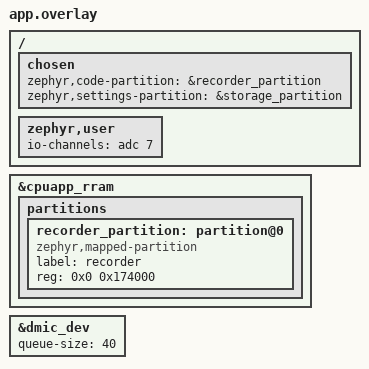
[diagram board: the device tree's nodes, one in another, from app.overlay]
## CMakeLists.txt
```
cmake_minimum_required(VERSION 3.20.0)
find_package(Zephyr REQUIRED HINTS $ENV{ZEPHYR_BASE})
project(recorder)

include(${CMAKE_CURRENT_SOURCE_DIR}/../lib/opus.cmake)

target_sources(app PRIVATE src/main.c src/audio.c src/ble.c src/battery.c src/agc.c)
target_link_libraries(app PRIVATE opus)
```

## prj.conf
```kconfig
# ---- 基础 ----
CONFIG_PRINTK=y
CONFIG_GPIO=y
CONFIG_LOG=y
CONFIG_MAIN_STACK_SIZE=4096

# ---- 麦克风 ----
CONFIG_AUDIO=y
CONFIG_AUDIO_DMIC=y

# ---- 蓝牙 ----
CONFIG_BT=y
CONFIG_BT_PERIPHERAL=y
CONFIG_BT_DEVICE_NAME="Hark DT-1"
CONFIG_BT_MAX_CONN=1
# 无显示屏：LE Secure Connections Just Works，禁用 legacy pairing。
CONFIG_BT_SMP=y
CONFIG_BT_SMP_SC_PAIR_ONLY=y
CONFIG_BT_SMP_APP_PAIRING_ACCEPT=y
CONFIG_BT_BONDABLE=y
CONFIG_BT_MAX_PAIRED=2
CONFIG_BT_KEYS_OVERWRITE_OLDEST=n
# 同一手机忘记密钥后也能在按键窗口内重新配对；窗口外由 pairing_accept 拒绝。
CONFIG_BT_SMP_ALLOW_UNAUTH_OVERWRITE=y
CONFIG_BT_SETTINGS=y
CONFIG_SETTINGS=y
CONFIG_FLASH=y
CONFIG_FLASH_MAP=y
CONFIG_FLASH_PAGE_LAYOUT=y
CONFIG_ZMS=y
CONFIG_SETTINGS_ZMS=y
CONFIG_USE_DT_CODE_PARTITION=y
# 大包：一次通知能带一整帧 Opus
CONFIG_BT_L2CAP_TX_MTU=247
CONFIG_BT_BUF_ACL_TX_SIZE=251
CONFIG_BT_BUF_ACL_RX_SIZE=251
CONFIG_BT_CTLR_DATA_LENGTH_MAX=251
CONFIG_BT_BUF_ACL_TX_COUNT=10
CONFIG_BT_CONN_TX_MAX=10
CONFIG_BT_GAP_AUTO_UPDATE_CONN_PARAMS=y
CONFIG_BT_PERIPHERAL_PREF_MIN_INT=12
CONFIG_BT_PERIPHERAL_PREF_MAX_INT=24
CONFIG_BT_PERIPHERAL_PREF_LATENCY=0
CONFIG_BT_PERIPHERAL_PREF_TIMEOUT=400
CONFIG_BT_USER_DATA_LEN_UPDATE=y
CONFIG_BT_USER_PHY_UPDATE=y

# ---- Opus 需要较大的栈和堆 ----
CONFIG_HEAP_MEM_POOL_SIZE=32768
CONFIG_FPU=y
CONFIG_BT_BUF_EVT_RX_COUNT=12

# ---- 电池电压 ----
CONFIG_ADC=y
CONFIG_REGULATOR=y

# ---- 出错自动重启：否则一旦出错芯片就停在原地，只有断电才能恢复 ----
CONFIG_REBOOT=y
CONFIG_RESET_ON_FATAL_ERROR=y
```

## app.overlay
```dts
/* 电池电压：ADC 通道 7 (P1.14)，经过 1/2 分压；vbat_pwr 负载开关控制分压电路的通断 */
/ {
	chosen {
		zephyr,code-partition = &recorder_partition;
		zephyr,settings-partition = &storage_partition;
	};
	zephyr,user {
		io-channels = <&adc 7>;
	};
};

/* 裸机程序仍从 0 启动。沿用 SDK 的 0x174000..0x17cfff settings 区，
 * 链接器限制程序不能进入该区，HEX 也不会包含该区。没有 MCUboot/双槽升级。 */
/delete-node/ &boot_partition;
/delete-node/ &slot0_partition;
/delete-node/ &slot1_partition;

&cpuapp_rram {
	partitions {
		recorder_partition: partition@0 {
			compatible = "zephyr,mapped-partition";
			label = "recorder";
			reg = <0x0 0x174000>;
		};
	};
};

/* PDM 驱动的接收队列默认只有 4 块 (80ms)。开口时要一口气编码 0.4 秒缓存（约 100ms），
 * 队列一满驱动就停麦且不恢复（2026-11-11 实测每几分钟一次）。40 块 = 0.8 秒，
 * 驱动另占 2 块，所以 audio.c 的 BLOCK_COUNT 必须 ≥ 42。 */
&dmic_dev {
	queue-size = <40>;
};
```

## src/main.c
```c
/* 全天语音记录器 —— 录音 + Opus 编码 + BLE 实时发送 */
#include <zephyr/kernel.h>
#include "app.h"

int main(void)
{
	printk("\n=== Hark DT-1 recorder start ===\n");
	if (ble_init() != 0) {
		printk("ERROR: BLE init failed\n");
		return 0;
	}
	audio_start();
	return 0;
}
```

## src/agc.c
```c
/*
 * 音频前处理：80Hz 高通滤波 + 固定线性增益（+12dB）+ 峰值限制防削波。
 *
 * - 高通：二阶巴特沃斯，去掉直流、走路震动、衣服摩擦、空调等低频轰鸣（人声基本在 100Hz 以上）。
 * - 固定增益：不再做 0~20dB 动态响度拉平，完整保留物理声压差（供手机端远近场判别，同时避免时变增益劣化声纹）。
 * - 峰值限制：放大后若瞬时峰值超过 -1dBFS（如咳嗽、碰壳），当帧立即压到刚好不削波，之后按 50dB/s 平滑恢复到 +12dB，无咔哒声。
 */
#include <math.h>
#include <zephyr/sys/util.h>
#include "agc.h"
#include "app.h"

#define HPF_HZ            80.0f
#define FIXED_GAIN_DB     12.0f                       /* 固定 ×4 线性放大，保留真实远近音量差 */
#define RECOVER_DB_PER_FR (50.0f * FRAME_MS / 1000.0f)/* 限幅后每帧恢复 1dB（约 0.2 秒回到 +12dB） */
#define PEAK_LIMIT        (0.89f * 32767.0f)          /* -1dBFS */
#define GATE_DB           8.0f       /* 比噪声底高这么多就当作"有声音"，宁可多发不漏字 */

static float b0, b1, b2, a1, a2;     /* 高通系数 */
static float hx1, hx2, hy1, hy2;     /* 高通状态 */
static float gain_db = FIXED_GAIN_DB;
static float gain_lin_prev;
static float noise_db = -60.0f;
static uint32_t limited;
static float buf[FRAME_SAMPLES];
static bool voice;

void agc_init(void)
{
	/* RBJ cookbook 高通，Q = 1/sqrt(2) */
	float w0 = 2.0f * 3.14159265f * HPF_HZ / SAMPLE_RATE;
	float alpha = sinf(w0) / (2.0f * 0.70710678f);
	float c = cosf(w0), a0 = 1.0f + alpha;
	b0 = (1.0f + c) / 2.0f / a0;
	b1 = -(1.0f + c) / a0;
	b2 = (1.0f + c) / 2.0f / a0;
	a1 = -2.0f * c / a0;
	a2 = (1.0f - alpha) / a0;
	hx1 = hx2 = hy1 = hy2 = 0;
	gain_db = FIXED_GAIN_DB;
	gain_lin_prev = powf(10.0f, gain_db / 20.0f);
}

static inline float db(float lin)
{
	return 20.0f * log10f(lin + 1e-9f);
}

void agc_process(int16_t *pcm, int n)
{
	n = MIN(n, FRAME_SAMPLES);

	/* 1. 高通，同时求能量和峰值 */
	float sum_sq = 0, peak = 0;
	for (int i = 0; i < n; i++) {
		float x = pcm[i];
		float y = b0 * x + b1 * hx1 + b2 * hx2 - a1 * hy1 - a2 * hy2;
		hx2 = hx1; hx1 = x; hy2 = hy1; hy1 = y;
		buf[i] = y;
		sum_sq += y * y;
		float a = fabsf(y);
		if (a > peak) {
			peak = a;
		}
	}
	float rms_db = db(sqrtf(sum_sq / n) / 32768.0f);

	/* 2. 噪声底：跟踪最小值，下降很快、上升很慢（约 1dB/秒） */
	if (rms_db < noise_db) {
		noise_db = rms_db;
	} else {
		noise_db += 1.0f * FRAME_MS / 1000.0f;
	}

	voice = rms_db > noise_db + GATE_DB && rms_db > -80.0f;

	/* 3. 固定 +12dB 增益；若上一帧因瞬时大音量触发过限幅，平滑回升到 +12dB */
	if (gain_db < FIXED_GAIN_DB) {
		gain_db = MIN(FIXED_GAIN_DB, gain_db + RECOVER_DB_PER_FR);
	}

	/* 4. 峰值限制：这一帧放大后不能超过 -1dBFS */
	float g = powf(10.0f, gain_db / 20.0f);
	if (peak * g > PEAK_LIMIT) {
		g = PEAK_LIMIT / peak;
		gain_db = db(g);          /* 记住压低后的增益，之后再平滑回到 +12dB */
		limited++;
	}

	/* 5. 帧内从上一帧增益平滑过渡到这一帧增益 */
	float step = (g - gain_lin_prev) / n;
	float cur = gain_lin_prev;
	for (int i = 0; i < n; i++) {
		cur += step;
		float v = buf[i] * cur;
		pcm[i] = (int16_t)CLAMP(lrintf(v), -32768, 32767);
	}
	gain_lin_prev = g;
}

bool agc_voice(void) { return voice; }
float agc_gain_db(void) { return gain_db; }
float agc_noise_db(void) { return noise_db; }
uint32_t agc_limited_frames(void) { return limited; }
```

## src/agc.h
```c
#pragma once
#include <stdint.h>
#include <stdbool.h>

/* 80Hz 高通 + 自动增益（带峰值限制），原地处理一帧 16-bit PCM */
void agc_init(void);
void agc_process(int16_t *pcm, int n);

/* 上一帧像不像有声音（比噪声底高 GATE_DB 以上）。用来决定安静时不发送 */
bool agc_voice(void);

/* 统计（给串口打印用） */
float agc_gain_db(void);
float agc_noise_db(void);
uint32_t agc_limited_frames(void);   /* 因为峰值而被压低增益的帧数 */
```

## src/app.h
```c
#pragma once
#include <stdint.h>
#include <stdbool.h>
#include <stddef.h>

/* 采样参数 */
#define SAMPLE_RATE    16000
#define FRAME_MS       20
#define FRAME_SAMPLES  (SAMPLE_RATE * FRAME_MS / 1000)   /* 320 */
#define OPUS_BITRATE   16000
#define OPUS_MAX_BYTES 120

/* ble.c */
int ble_init(void);
bool ble_streaming(void);              /* 已加密且手机订阅了音频 */
void ble_recording(bool active);       /* 绿灯：窗口闪烁优先于录音常亮 */
/* 发一帧音频，seq 是帧序号（每 20ms 加一，安静没发的帧也算）。
 * len == 0 表示"安静声明"：seq 以及之前没收到的帧都是安静，手机用静音补上 */
int ble_send_audio(uint16_t seq, const uint8_t *data, size_t len);

/* ble.c 电池 */
int ble_send_battery(uint16_t mv);

/* battery.c */
uint16_t battery_mv(void);

/* audio.c */
void audio_start(void);
```

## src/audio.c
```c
/* 音频：PDM 麦克风 16kHz → 高通 + 自动增益 → Opus 编码 → BLE 发送。
 * 只在手机订阅了音频时才开麦，省电。
 *
 * 安静时不编码、不发送（省设备和手机的电）：
 * - 每帧都过 AGC，顺便判断"有没有声音"；最近 10 帧里有 3 帧有声音就开始发送
 * - 开始发送时，把之前缓存的 0.4 秒也补发出去，免得丢掉第一个字
 * - 最后一次有声音后再继续发 3 秒，免得把句子中间的停顿切掉
 * - 不发送期间，每秒发一个只有帧序号的"安静声明"，手机据此用静音补齐，时间线不乱
 */
#include <zephyr/kernel.h>
#include <zephyr/audio/dmic.h>
#include <opus.h>
#include "app.h"
#include "agc.h"

#define BLOCK_BYTES  (FRAME_SAMPLES * 2)
#define BLOCK_COUNT  50                   /* 50 × 20ms = 1s 缓冲：开口时要一口气编码 0.4s 缓存，蓝牙拥塞时发送也会等；用完驱动就停 */
#define PREROLL      20                   /* 开口前补发 0.4 秒 */
#define HANG         150                  /* 声音停了以后再发 3 秒 */
#define ONSET_WIN    10                   /* 最近 10 帧里 */
#define ONSET_MIN    3                    /* 有 3 帧有声音就开始发 */
#define KEEPALIVE    50                   /* 安静时每 1 秒声明一次 */
#define STATS_EVERY  250                  /* 每 250 帧 (5 秒) 打印一次统计 */

K_MEM_SLAB_DEFINE_STATIC(pcm_slab, BLOCK_BYTES, BLOCK_COUNT, 4);

static const struct device *dmic = DEVICE_DT_GET(DT_NODELABEL(dmic_dev));

static uint8_t enc_mem[28 * 1024] __aligned(8);
static int16_t ring[PREROLL][FRAME_SAMPLES];   /* 最近 0.4 秒处理过的 PCM，按帧号取模存放 */
static OpusEncoder *enc;

static int mic_config(void)
{
	static struct pcm_stream_cfg stream = {
		.pcm_rate = SAMPLE_RATE, .pcm_width = 16,
		.block_size = BLOCK_BYTES, .mem_slab = &pcm_slab,
	};
	struct dmic_cfg cfg = {
		.io = { .min_pdm_clk_freq = 1000000, .max_pdm_clk_freq = 3500000,
			.min_pdm_clk_dc = 40, .max_pdm_clk_dc = 60 },
		.streams = &stream,
		.channel = { .req_num_streams = 1, .req_num_chan = 1,
			     .req_chan_map_lo = dmic_build_channel_map(0, 0, PDM_CHAN_LEFT) },
	};
	return dmic_configure(dmic, &cfg);
}

static int encoder_init(void)
{
	int size = opus_encoder_get_size(1);
	printk("opus encoder size: %d bytes\n", size);
	if (size > sizeof(enc_mem)) {
		return -ENOMEM;
	}
	enc = (OpusEncoder *)enc_mem;
	int err = opus_encoder_init(enc, SAMPLE_RATE, 1, OPUS_APPLICATION_VOIP);
	if (err != OPUS_OK) {
		return err;
	}
	opus_encoder_ctl(enc, OPUS_SET_BITRATE(OPUS_BITRATE));
	opus_encoder_ctl(enc, OPUS_SET_VBR(1));
	opus_encoder_ctl(enc, OPUS_SET_COMPLEXITY(1));
	opus_encoder_ctl(enc, OPUS_SET_SIGNAL(OPUS_SIGNAL_VOICE));
	opus_encoder_ctl(enc, OPUS_SET_BANDWIDTH(OPUS_BANDWIDTH_WIDEBAND));
	return 0;
}

static void drain_mic(void)
{
	void *buf;
	uint32_t size;

	while (dmic_read(dmic, 0, &buf, &size, 0) == 0) {
		k_mem_slab_free(&pcm_slab, buf);
	}
}

static int encode_send(uint32_t seq, uint8_t *out, uint32_t *bytes, uint32_t *enc_us_sum, uint32_t *enc_us_max)
{
	uint32_t t0 = k_cycle_get_32();
	int n = opus_encode(enc, ring[seq % PREROLL], FRAME_SAMPLES, out, OPUS_MAX_BYTES);
	uint32_t us = k_cyc_to_us_floor32(k_cycle_get_32() - t0);

	if (n < 0) {
		printk("opus error %d\n", n);
		return n;
	}
	*bytes += n;
	*enc_us_sum += us;
	*enc_us_max = MAX(*enc_us_max, us);
	return ble_send_audio((uint16_t)seq, out, n);
}

static void stream_session(void)
{
	uint8_t out[OPUS_MAX_BYTES];
	uint32_t frames = 0, sent = 0, sent_period = 0, bytes = 0, send_err = 0, enc_us_sum = 0, enc_us_max = 0;
	uint32_t seq = 0;          /* 下一帧的帧号（32 位，发出去时取低 16 位） */
	uint32_t next_open = 0;    /* 第一个既没发送、也没声明为安静的帧 */
	uint32_t last_ka = 0;
	uint16_t hist = 0;         /* 最近 ONSET_WIN 帧有没有声音，一位一帧 */
	int hang = 0;              /* > 0 表示正在发送 */

	if (dmic_trigger(dmic, DMIC_TRIGGER_START) < 0) {
		printk("ERROR: mic start failed\n");
		k_msleep(1000);
		return;
	}
	agc_init();
	opus_encoder_ctl(enc, OPUS_RESET_STATE);
	ble_recording(true);
	printk("mic ON\n");

	while (ble_streaming()) {
		void *buf;
		uint32_t size;

		if (dmic_read(dmic, 0, &buf, &size, 500) < 0) {
			/* 缓冲一旦用完，nrfx PDM 驱动会自己停掉且不再恢复，只能重启麦克风。
			 * 卡住的这段按时长跳过帧号，之后的安静声明让手机用静音补齐，时间线不缩短。 */
			printk("mic read timeout, restarting mic\n");
			seq += 500 / FRAME_MS;
			dmic_trigger(dmic, DMIC_TRIGGER_STOP);
			drain_mic();
			if (dmic_trigger(dmic, DMIC_TRIGGER_START) < 0) {
				printk("ERROR: mic restart failed\n");
				k_msleep(1000);
			}
			continue;
		}
		agc_process(buf, size / 2);
		bool v = agc_voice();
		uint32_t cur = seq++;
		memcpy(ring[cur % PREROLL], buf, FRAME_SAMPLES * 2);
		k_mem_slab_free(&pcm_slab, buf);
		frames++;
		hist = ((hist << 1) | v) & ((1u << ONSET_WIN) - 1);

		if (hang > 0) {
			/* 正在发送 */
			if (encode_send(cur, out, &bytes, &enc_us_sum, &enc_us_max) != 0) {
				send_err++;
			}
			sent++;
			sent_period++;
			next_open = cur + 1;
			hang = v ? HANG : hang - 1;
		} else if (__builtin_popcount(hist) >= ONSET_MIN) {
			/* 开口了：先声明缓存之前的帧是安静，再把缓存的帧和这一帧发出去 */
			uint32_t start = cur + 1 > PREROLL ? cur + 1 - PREROLL : 0;
			start = MAX(start, next_open);
			if (start > next_open) {
				ble_send_audio((uint16_t)(start - 1), NULL, 0);
			}
			opus_encoder_ctl(enc, OPUS_RESET_STATE);
			for (uint32_t s = start; s <= cur; s++) {
				if (encode_send(s, out, &bytes, &enc_us_sum, &enc_us_max) != 0) {
					send_err++;
				}
				sent++;
				sent_period++;
			}
			next_open = cur + 1;
			hang = HANG;
		} else if (cur - last_ka >= KEEPALIVE && cur + 1 > PREROLL) {
			/* 安静：声明到缓存之前为止都是安静（缓存里的帧可能还要补发） */
			uint32_t upto = cur + 1 - PREROLL - 1;
			if (upto + 1 > next_open) {
				ble_send_audio((uint16_t)upto, NULL, 0);
				next_open = upto + 1;
			}
			last_ka = cur;
		}

		if (frames % STATS_EVERY == 0) {
			printk("[stats] %u frames, sent %u%%, %u B/s, encode avg %u us max %u us, send errors %u, "
			       "gain %d dB, noise %d dBFS, limited %u\n",
			       frames, sent * 100 / frames, bytes * 1000 / (STATS_EVERY * FRAME_MS),
			       enc_us_sum / MAX(1, sent_period), enc_us_max, send_err,
			       (int)agc_gain_db(), (int)agc_noise_db(), agc_limited_frames());
			bytes = enc_us_sum = enc_us_max = sent_period = 0;
		}
	}

	dmic_trigger(dmic, DMIC_TRIGGER_STOP);
	drain_mic();
	ble_recording(false);
	printk("mic OFF\n");
}

static void audio_thread(void *a, void *b, void *c)
{
	if (!device_is_ready(dmic) || mic_config() < 0) {
		printk("ERROR: mic init failed\n");
		return;
	}
	if (encoder_init() != 0) {
		printk("ERROR: opus init failed\n");
		return;
	}
	printk("audio ready, waiting for phone to subscribe\n");

	for (;;) {
		if (ble_streaming()) {
			stream_session();
		} else {
			k_msleep(100);
		}
	}
}

/* Opus 用变长数组放在栈上，需要较大的栈 */
K_THREAD_STACK_DEFINE(audio_stack, 32 * 1024);
static struct k_thread audio_tid;

void audio_start(void)
{
	k_thread_create(&audio_tid, audio_stack, K_THREAD_STACK_SIZEOF(audio_stack),
			audio_thread, NULL, NULL, NULL, 5, K_FP_REGS, K_NO_WAIT);
}
```

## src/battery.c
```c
/* 电池电压测量：每 30 秒测一次，打印到串口，并通过 BLE 通知。 */
#include <zephyr/kernel.h>
#include <zephyr/drivers/adc.h>
#include <zephyr/drivers/regulator.h>
#include "app.h"

#define MEASURE_PERIOD_S 30

static const struct adc_dt_spec vbat_adc = ADC_DT_SPEC_GET_BY_IDX(DT_PATH(zephyr_user), 0);
static const struct device *vbat_sw = DEVICE_DT_GET(DT_NODELABEL(vbat_pwr));
static volatile uint16_t last_mv;

static int measure_mv(void)
{
	int16_t raw;
	int32_t mv;
	struct adc_sequence seq = { .buffer = &raw, .buffer_size = sizeof(raw) };

	regulator_enable(vbat_sw);          /* 接通分压电路 */
	k_msleep(10);
	adc_sequence_init_dt(&vbat_adc, &seq);
	int err = adc_read_dt(&vbat_adc, &seq);
	regulator_disable(vbat_sw);         /* 测完断开，省电 */
	if (err) {
		return err;
	}
	mv = raw;
	adc_raw_to_millivolts_dt(&vbat_adc, &mv);
	return mv * 2;                      /* 1/2 分压 */
}

uint16_t battery_mv(void)
{
	return last_mv;
}

static void battery_thread(void *a, void *b, void *c)
{
	if (!adc_is_ready_dt(&vbat_adc) || adc_channel_setup_dt(&vbat_adc) < 0) {
		printk("ERROR: battery ADC init failed\n");
		return;
	}
	for (;;) {
		int mv = measure_mv();
		if (mv > 0) {
			last_mv = mv;
			printk("[battery] %d mV, uptime %llds\n", mv, k_uptime_get() / 1000);
			ble_send_battery(mv);
		}
		k_sleep(K_SECONDS(MEASURE_PERIOD_S));
	}
}

K_THREAD_DEFINE(battery_tid, 1024, battery_thread, NULL, NULL, NULL, 7, 0, 2000);
```

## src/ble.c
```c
/* BLE：加密音频服务。按键只打开配对窗口，新配对成功才替换旧密钥。 */
#include <zephyr/kernel.h>
#include <zephyr/bluetooth/bluetooth.h>
#include <zephyr/bluetooth/conn.h>
#include <zephyr/bluetooth/gatt.h>
#include <zephyr/bluetooth/hci.h>
#include <zephyr/bluetooth/uuid.h>
#include <zephyr/drivers/gpio.h>
#include <zephyr/settings/settings.h>
#include <zephyr/sys/atomic.h>
#include <zephyr/sys/byteorder.h>
#include <string.h>
#include "app.h"

#define RIG_UUID(n) BT_UUID_128_ENCODE(0x5a1d0000 | (n), 0x7e3c, 0x4b8a, 0x9f00, 0x524947000000)
#define PAIR_WINDOW_MS 60000
#define UNENCRYPTED_MS 15000
#define DEBOUNCE_MS 30 /* 机械按键稳定 30ms 后采样；长按只触发一次 */

static const struct bt_uuid_128 svc_uuid   = BT_UUID_INIT_128(RIG_UUID(1));
static const struct bt_uuid_128 audio_uuid = BT_UUID_INIT_128(RIG_UUID(2));
static const struct bt_uuid_128 batt_uuid  = BT_UUID_INIT_128(RIG_UUID(3));
static const struct gpio_dt_spec led = GPIO_DT_SPEC_GET(DT_ALIAS(led0), gpios);
static const struct gpio_dt_spec button = GPIO_DT_SPEC_GET(DT_ALIAS(sw0), gpios);
static struct gpio_callback button_cb;
static struct k_spinlock state_lock;
static struct bt_conn *cur_conn;
static int64_t pairing_deadline, security_deadline;
static bool recording, button_pressed, led_on;
enum { AUDIO_CCC, BATT_CCC, ENCRYPTED };
static atomic_t flags;
static atomic_t adv_after_recycle;
static struct k_work adv_work;
static struct k_work_delayable window_work, led_work, button_work, security_work;

static struct bt_conn *connection_ref(void)
{
	k_spinlock_key_t key = k_spin_lock(&state_lock);
	struct bt_conn *conn = cur_conn ? bt_conn_ref(cur_conn) : NULL;
	k_spin_unlock(&state_lock, key);
	return conn;
}

static int64_t window_remaining(void)
{
	k_spinlock_key_t key = k_spin_lock(&state_lock);
	int64_t remaining = pairing_deadline - k_uptime_get();
	k_spin_unlock(&state_lock, key);
	return MAX(remaining, 0);
}

static void batt_ccc_changed(const struct bt_gatt_attr *attr, uint16_t value)
{
	atomic_set_bit_to(&flags, BATT_CCC, value == BT_GATT_CCC_NOTIFY);
}

static ssize_t batt_read(struct bt_conn *conn, const struct bt_gatt_attr *attr,
			 void *buf, uint16_t len, uint16_t offset)
{
	uint16_t mv = sys_cpu_to_le16(battery_mv());
	return bt_gatt_attr_read(conn, attr, buf, len, offset, &mv, sizeof(mv));
}

static void ccc_changed(const struct bt_gatt_attr *attr, uint16_t value)
{
	atomic_set_bit_to(&flags, AUDIO_CCC, value == BT_GATT_CCC_NOTIFY);
}

BT_GATT_SERVICE_DEFINE(rig_svc,
	BT_GATT_PRIMARY_SERVICE(&svc_uuid),
	BT_GATT_CHARACTERISTIC(&audio_uuid.uuid, BT_GATT_CHRC_NOTIFY,
			       BT_GATT_PERM_NONE, NULL, NULL, NULL),
	BT_GATT_CCC(ccc_changed, BT_GATT_PERM_READ_ENCRYPT | BT_GATT_PERM_WRITE_ENCRYPT),
	BT_GATT_CHARACTERISTIC(&batt_uuid.uuid, BT_GATT_CHRC_READ | BT_GATT_CHRC_NOTIFY,
			       BT_GATT_PERM_READ_ENCRYPT, batt_read, NULL, NULL),
	BT_GATT_CCC(batt_ccc_changed, BT_GATT_PERM_READ_ENCRYPT | BT_GATT_PERM_WRITE_ENCRYPT),
);

/* 128-bit service data：本服务 UUID + 版本/配对标记 01。
 * 普通广播 21 字节，窗口广播 22 字节，名称放 scan response，均在 31 字节内。 */
static const struct bt_data ad[] = {
	BT_DATA_BYTES(BT_DATA_FLAGS, (BT_LE_AD_GENERAL | BT_LE_AD_NO_BREDR)),
	BT_DATA_BYTES(BT_DATA_UUID128_ALL, RIG_UUID(1)),
};
static const struct bt_data pair_ad[] = {
	BT_DATA_BYTES(BT_DATA_FLAGS, (BT_LE_AD_GENERAL | BT_LE_AD_NO_BREDR)),
	BT_DATA_BYTES(BT_DATA_SVC_DATA128, RIG_UUID(1), 0x01),
};
static const struct bt_data sd[] = {
	BT_DATA(BT_DATA_NAME_COMPLETE, CONFIG_BT_DEVICE_NAME, sizeof(CONFIG_BT_DEVICE_NAME) - 1),
};

static void adv_start(struct k_work *w)
{
	/* 开关窗口时必须换掉广播里的标记。已连接时等 recycled 再广播。 */
	bt_le_adv_stop();
	struct bt_conn *conn = connection_ref();
	if (conn) {
		bt_conn_unref(conn);
		return;
	}
	bool pairing = window_remaining() > 0;
	const struct bt_data *data = pairing ? pair_ad : ad;
	size_t count = pairing ? ARRAY_SIZE(pair_ad) : ARRAY_SIZE(ad);
	int err = bt_le_adv_start(BT_LE_ADV_CONN_FAST_2, data, count, sd, ARRAY_SIZE(sd));
	if (err && err != -EALREADY) {
		printk("adv start failed: %d\n", err);
	}
}

static void led_update(struct k_work *w)
{
	bool pairing = window_remaining() > 0;
	k_spinlock_key_t key = k_spin_lock(&state_lock);
	bool active = recording;
	k_spin_unlock(&state_lock, key);
	led_on = pairing ? !led_on : active;
	gpio_pin_set_dt(&led, led_on);
	if (pairing) {
		k_work_reschedule(&led_work, K_MSEC(250));
	}
}

void ble_recording(bool active)
{
	k_spinlock_key_t key = k_spin_lock(&state_lock);
	recording = active;
	k_spin_unlock(&state_lock, key);
	if (window_remaining() == 0) {
		k_work_reschedule(&led_work, K_NO_WAIT);
	}
}

static void security_timeout(struct k_work *w)
{
	struct bt_conn *conn = connection_ref();
	if (!conn) {
		return;
	}
	k_spinlock_key_t key = k_spin_lock(&state_lock);
	int64_t remaining = security_deadline - k_uptime_get();
	k_spin_unlock(&state_lock, key);
	if (bt_conn_get_security(conn) < BT_SECURITY_L2) {
		if (remaining > 0) {
			k_work_reschedule(&security_work, K_MSEC(remaining));
		} else {
			bt_conn_disconnect(conn, BT_HCI_ERR_AUTH_FAIL);
		}
	}
	bt_conn_unref(conn);
}

static void window_expired(struct k_work *w)
{
	int64_t remaining = window_remaining();
	if (remaining > 0) {
		k_work_reschedule(&window_work, K_MSEC(remaining));
		return;
	}
	k_work_submit(&adv_work);
	k_work_reschedule(&led_work, K_NO_WAIT);
	k_work_reschedule(&security_work, K_NO_WAIT);
	printk("pairing window closed\n");
}

static void button_debounced(struct k_work *w)
{
	int value = gpio_pin_get_dt(&button);
	if (value < 0 || (value > 0) == button_pressed) {
		return;
	}
	button_pressed = value > 0;
	if (!button_pressed) {
		return;
	}
	k_spinlock_key_t key = k_spin_lock(&state_lock);
	pairing_deadline = k_uptime_get() + PAIR_WINDOW_MS;
	k_spin_unlock(&state_lock, key);
	k_work_reschedule(&window_work, K_MSEC(PAIR_WINDOW_MS));
	k_work_reschedule(&led_work, K_NO_WAIT);
	/* MAX_CONN=1：让新手机有机会连进来，误按不删除任何 bond。 */
	struct bt_conn *conn = connection_ref();
	if (conn) {
		bt_conn_disconnect(conn, BT_HCI_ERR_REMOTE_USER_TERM_CONN);
		bt_conn_unref(conn);
	}
	k_work_submit(&adv_work);
	printk("pairing window open (60s)\n");
}

static void button_changed(const struct device *dev, struct gpio_callback *cb, uint32_t pins)
{
	k_work_reschedule(&button_work, K_MSEC(DEBOUNCE_MS));
}

static enum bt_security_err pairing_accept(struct bt_conn *conn,
					 const struct bt_conn_pairing_feat *const feat)
{
	return window_remaining() > 0 ? BT_SECURITY_ERR_SUCCESS : BT_SECURITY_ERR_PAIR_NOT_ALLOWED;
}

struct old_bonds {
	const bt_addr_le_t *keep;
	bt_addr_le_t peers[CONFIG_BT_MAX_PAIRED];
	size_t count;
};

static void collect_old_bond(const struct bt_bond_info *info, void *data)
{
	struct old_bonds *old = data;
	if (!bt_addr_le_eq(&info->addr, old->keep) && old->count < ARRAY_SIZE(old->peers)) {
		bt_addr_le_copy(&old->peers[old->count++], &info->addr);
	}
}

static void pairing_complete(struct bt_conn *conn, bool bonded)
{
	if (!bonded) {
		bt_conn_disconnect(conn, BT_HCI_ERR_AUTH_FAIL);
		return;
	}
	/* Zephyr 已先持久化新密钥。先收集后删除，避免在遍历时改 bond 表。 */
	struct old_bonds old = { .keep = bt_conn_get_dst(conn) };
	bt_foreach_bond(BT_ID_DEFAULT, collect_old_bond, &old);
	for (size_t i = 0; i < old.count; i++) {
		int err = bt_unpair(BT_ID_DEFAULT, &old.peers[i]);
		if (err) {
			printk("old bond removal failed: %d\n", err);
		}
	}
	printk("pairing complete\n");
}

static void pairing_failed(struct bt_conn *conn, enum bt_security_err reason)
{
	bt_conn_disconnect(conn, BT_HCI_ERR_AUTH_FAIL);
}

static const struct bt_conn_auth_cb auth_cb = { .pairing_accept = pairing_accept };
static struct bt_conn_auth_info_cb auth_info_cb = {
	.pairing_complete = pairing_complete,
	.pairing_failed = pairing_failed,
};

static void connected(struct bt_conn *conn, uint8_t err)
{
	if (err) {
		printk("connect failed: %u\n", err);
		atomic_set(&adv_after_recycle, 1);
		return;
	}
	/* CCC 可能在 connected 回调之前已经从 settings 恢复，不能清掉它。 */
	atomic_clear_bit(&flags, ENCRYPTED);
	k_spinlock_key_t key = k_spin_lock(&state_lock);
	cur_conn = bt_conn_ref(conn);
	int64_t now = k_uptime_get();
	security_deadline = pairing_deadline > now ? pairing_deadline : now + UNENCRYPTED_MS;
	int64_t timeout = security_deadline - now;
	k_spin_unlock(&state_lock, key);
	k_work_reschedule(&security_work, K_MSEC(timeout));
	printk("connected\n");

	bt_conn_le_phy_update(conn, BT_CONN_LE_PHY_PARAM_2M);
	struct bt_conn_le_data_len_param dl = { .tx_max_len = 251, .tx_max_time = 2120 };
	bt_conn_le_data_len_update(conn, &dl);
	/* Android 在完成 bond 前不做 GATT 操作；已配对设备也需主动恢复加密。
	 * 无旧密钥时不在这里发起配对，由手机 createBond / 受保护的 GATT 请求触发。 */
	if (bt_le_bond_exists(BT_ID_DEFAULT, bt_conn_get_dst(conn))) {
		bt_conn_set_security(conn, BT_SECURITY_L2);
	}
}

static void security_changed(struct bt_conn *conn, bt_security_t level, enum bt_security_err err)
{
	atomic_set_bit_to(&flags, ENCRYPTED, !err && level >= BT_SECURITY_L2);
	if (err) {
		bt_conn_disconnect(conn, BT_HCI_ERR_AUTH_FAIL);
	} else if (level >= BT_SECURITY_L2) {
		k_work_cancel_delayable(&security_work);
	}
}

static void disconnected(struct bt_conn *conn, uint8_t reason)
{
	atomic_clear(&flags);
	atomic_set(&adv_after_recycle, 1);
	k_work_cancel_delayable(&security_work);
	k_spinlock_key_t key = k_spin_lock(&state_lock);
	struct bt_conn *old = cur_conn;
	cur_conn = NULL;
	k_spin_unlock(&state_lock, key);
	if (old) {
		bt_conn_unref(old);
	}
	printk("disconnected (reason %u)\n", reason);
}

static void recycled(void)
{
	/* bt_le_adv_stop 释放可连接广播的连接对象时也会走到这里。
	 * 只有真正断开过才重启广播，否则 adv_start 的停止动作会造成死循环。 */
	if (atomic_cas(&adv_after_recycle, 1, 0)) {
		k_work_submit(&adv_work);
	}
}

BT_CONN_CB_DEFINE(conn_cb) = {
	.connected = connected,
	.disconnected = disconnected,
	.recycled = recycled,
	.security_changed = security_changed,
};

static void mtu_updated(struct bt_conn *conn, uint16_t tx, uint16_t rx)
{
	printk("MTU: tx %u rx %u\n", tx, rx);
}

static struct bt_gatt_cb gatt_cb = { .att_mtu_updated = mtu_updated };

int ble_init(void)
{
	if (!gpio_is_ready_dt(&led) || !gpio_is_ready_dt(&button)) {
		return -ENODEV;
	}
	int err = gpio_pin_configure_dt(&led, GPIO_OUTPUT_INACTIVE);
	if (err) {
		return err;
	}
	k_work_init(&adv_work, adv_start);
	k_work_init_delayable(&window_work, window_expired);
	k_work_init_delayable(&led_work, led_update);
	k_work_init_delayable(&button_work, button_debounced);
	k_work_init_delayable(&security_work, security_timeout);
	err = bt_conn_auth_cb_register(&auth_cb);
	if (!err) {
		err = bt_conn_auth_info_cb_register(&auth_info_cb);
	}
	if (!err) {
		err = bt_enable(NULL);
	}
	if (!err) {
		err = settings_load();
	}
	if (err) {
		return err; /* settings 不可用时不广播，不能假装配对已经持久化 */
	}
	bt_gatt_cb_register(&gatt_cb);
	err = gpio_pin_configure_dt(&button, GPIO_INPUT);
	if (err) {
		return err;
	}
	button_pressed = gpio_pin_get_dt(&button) > 0;
	gpio_init_callback(&button_cb, button_changed, BIT(button.pin));
	err = gpio_add_callback(button.port, &button_cb);
	if (!err) {
		err = gpio_pin_interrupt_configure_dt(&button, GPIO_INT_EDGE_BOTH);
	}
	if (err) {
		return err;
	}
	k_work_submit(&adv_work);
	return 0;
}

bool ble_streaming(void)
{
	/* 包括从 settings 恢复 CCC 的情况：加密前绝不开麦。 */
	return atomic_test_bit(&flags, ENCRYPTED) && atomic_test_bit(&flags, AUDIO_CCC);
}

int ble_send_audio(uint16_t seq, const uint8_t *data, size_t len)
{
	uint8_t pkt[2 + OPUS_MAX_BYTES];
	struct bt_conn *conn = connection_ref();
	if (!conn) {
		return -ENOTCONN;
	}
	int err = -ENOTCONN;
	if (!ble_streaming() || len > OPUS_MAX_BYTES) {
		goto out;
	}
	if (len + 2 > bt_gatt_get_mtu(conn) - 3) {
		err = -EMSGSIZE;
		goto out;
	}
	sys_put_le16(seq, pkt);
	if (len) {
		memcpy(&pkt[2], data, len);
	}
	for (int i = 0; i < 20; i++) {
		err = bt_gatt_notify(conn, &rig_svc.attrs[1], pkt, len + 2);
		if (err != -ENOMEM && err != -ENOBUFS) {
			break;
		}
		k_msleep(5);
	}
out:
	bt_conn_unref(conn);
	return err;
}

int ble_send_battery(uint16_t mv)
{
	struct bt_conn *conn = connection_ref();
	if (!conn) {
		return -ENOTCONN;
	}
	int err = -ENOTCONN;
	if (atomic_test_bit(&flags, ENCRYPTED) && atomic_test_bit(&flags, BATT_CCC)) {
		uint16_t v = sys_cpu_to_le16(mv);
		err = bt_gatt_notify(conn, &rig_svc.attrs[4], &v, sizeof(v));
	}
	bt_conn_unref(conn);
	return err;
}
```
